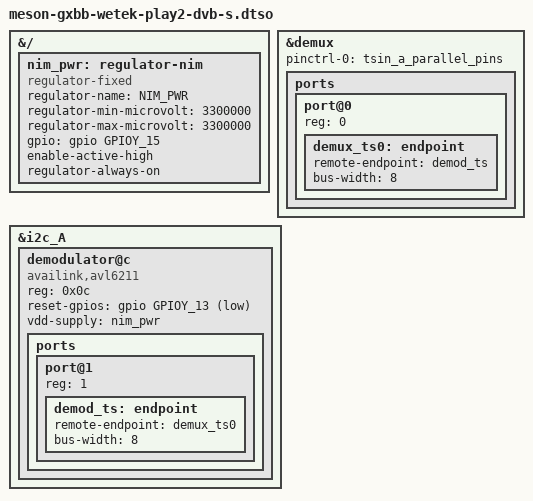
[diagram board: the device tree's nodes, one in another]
// SPDX-License-Identifier: (GPL-2.0+ OR MIT)
/*
 * WeTek Play 2 DVB-S/S2 card: Availink AVL6211 demodulator with the AV2011
 * tuner behind its I2C repeater, driven by the demodulator's driver
 */

/dts-v1/;
/plugin/;

#include <dt-bindings/gpio/gpio.h>
#include <dt-bindings/gpio/meson-gxbb-gpio.h>

&{/} {
	/* power of the card, also needed for its reset line */
	nim_pwr: regulator-nim {
		compatible = "regulator-fixed";
		regulator-name = "NIM_PWR";
		regulator-min-microvolt = <3300000>;
		regulator-max-microvolt = <3300000>;
		gpio = <&gpio GPIOY_15 GPIO_ACTIVE_HIGH>;
		enable-active-high;
		regulator-always-on;
	};
};

/* TS0 (tsin_a), parallel */
&demux {
	pinctrl-0 = <&tsin_a_parallel_pins>;
	pinctrl-names = "default";
	status = "okay";

	ports {
		#address-cells = <1>;
		#size-cells = <0>;

		port@0 {
			reg = <0>;

			demux_ts0: endpoint {
				remote-endpoint = <&demod_ts>;
				bus-width = <8>;
			};
		};
	};
};

&i2c_A {
	#address-cells = <1>;
	#size-cells = <0>;

	demodulator@c {
		compatible = "availink,avl6211";
		reg = <0x0c>;
		reset-gpios = <&gpio GPIOY_13 GPIO_ACTIVE_LOW>;
		/* orders the probe after the card power */
		vdd-supply = <&nim_pwr>;

		ports {
			#address-cells = <1>;
			#size-cells = <0>;

			port@1 {
				reg = <1>;

				demod_ts: endpoint {
					remote-endpoint = <&demux_ts0>;
					bus-width = <8>;
				};
			};
		};
	};
};
